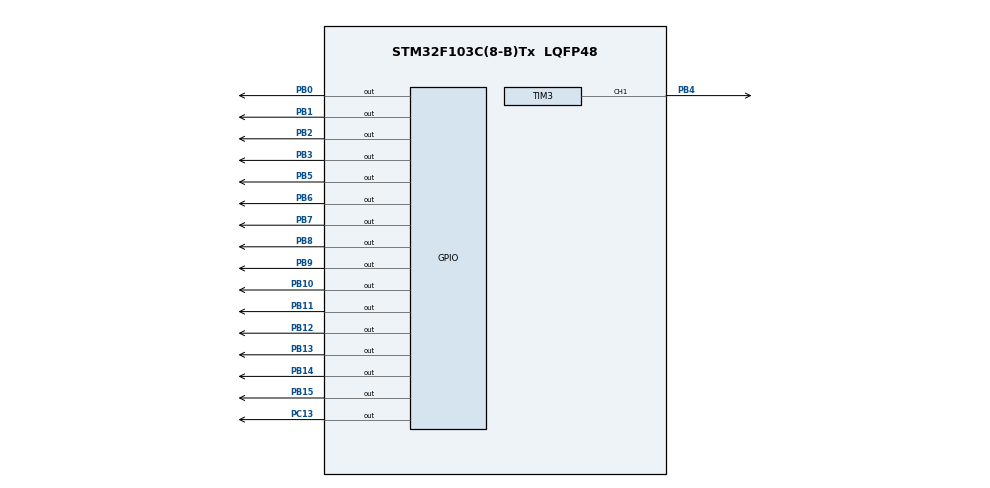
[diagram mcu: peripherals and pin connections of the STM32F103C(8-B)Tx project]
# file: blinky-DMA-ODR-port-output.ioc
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Dma.Request0=TIM1_UP
Dma.TIM1_UP.0.Direction=DMA_MEMORY_TO_PERIPH
Dma.TIM1_UP.0.Instance=DMA1_Channel5
Dma.TIM1_UP.0.MemDataAlignment=DMA_MDATAALIGN_HALFWORD
Dma.TIM1_UP.0.MemInc=DMA_MINC_ENABLE
Dma.TIM1_UP.0.Mode=DMA_CIRCULAR
Dma.TIM1_UP.0.PeriphDataAlignment=DMA_PDATAALIGN_HALFWORD
Dma.TIM1_UP.0.PeriphInc=DMA_PINC_DISABLE
Dma.TIM1_UP.0.Priority=DMA_PRIORITY_LOW
Mcu.Family=STM32F1
Mcu.Name=STM32F103C(8-B)Tx
Mcu.Package=LQFP48
NVIC.DMA1_Channel5_IRQn=true\:0\:0\:false\:false\:true\:false\:true
NVIC.PriorityGroup=NVIC_PRIORITYGROUP_4
PA13.Mode=Serial_Wire
PA13.Signal=SYS_JTMS-SWDIO
PA14.Mode=Serial_Wire
PA14.Signal=SYS_JTCK-SWCLK
PB0.Signal=GPIO_Output
PB1.Signal=GPIO_Output
PB10.Signal=GPIO_Output
PB11.Signal=GPIO_Output
PB12.Signal=GPIO_Output
PB13.Signal=GPIO_Output
PB14.Signal=GPIO_Output
PB15.Signal=GPIO_Output
PB2.Signal=GPIO_Output
PB3.Signal=GPIO_Output
PB4.Signal=S_TIM3_CH1
PB5.Signal=GPIO_Output
PB6.Signal=GPIO_Output
PB7.Signal=GPIO_Output
PB8.Signal=GPIO_Output
PB9.Signal=GPIO_Output
PC13-TAMPER-RTC.Signal=GPIO_Output
ProjectManager.HeapSize=0x200
ProjectManager.StackSize=0x400
ProjectManager.TargetToolchain=STM32CubeIDE
RCC.APB1Freq_Value=8000000
RCC.APB2Freq_Value=8000000
SH.S_TIM3_CH1.0=TIM3_CH1,PWM Generation1 CH1
TIM1.Channel-Output\ Compare1\ No\ Output=TIM_CHANNEL_1
TIM1.Period=999
TIM1.Prescaler=999
TIM1.Pulse-Output\ Compare1\ No\ Output=499
TIM3.Channel-PWM\ Generation1\ CH1=TIM_CHANNEL_1
TIM3.Period=0xff
TIM3.Prescaler=0xf
TIM3.Pulse-PWM\ Generation1\ CH1=0xea
VP_TIM1_VS_no_output1.Mode=Output Compare1 No Output
board=custom

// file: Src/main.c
/* USER CODE BEGIN Header */
/**
 ******************************************************************************
 * @file           : main.c
 * @brief          : Main program body
 ******************************************************************************
 * @attention
 *
 * <h2><center>&copy; Copyright (c) 2019 STMicroelectronics.
 * All rights reserved.</center></h2>
 *
 * This software component is licensed by ST under BSD 3-Clause license,
 * the "License"; You may not use this file except in compliance with the
 * License. You may obtain a copy of the License at:
 *                        opensource.org/licenses/BSD-3-Clause
 *
 ******************************************************************************
 */
/* USER CODE END Header */

#include "main.h"

TIM_HandleTypeDef htim1;
TIM_HandleTypeDef htim3;
DMA_HandleTypeDef hdma_tim1_up;

void SystemClock_Config(void);
static void MX_GPIO_Init(void);
static void MX_DMA_Init(void);
static void MX_TIM1_Init(void);
static void MX_TIM3_Init(void);

int main(void) {

	/* MCU Configuration--------------------------------------------------------*/

	/* Reset of all peripherals, Initializes the Flash interface and the Systick. */
	HAL_Init();

	/* Configure the system clock */
	SystemClock_Config();

	/* Initialize all configured peripherals */
	MX_GPIO_Init();
	MX_DMA_Init();
	MX_TIM1_Init();
	MX_TIM3_Init();
	/* USER CODE BEGIN 2 */
#define PATTERN_LENGTH 10
	/* In DMA step i, ODRx is set to pattern[i] bit x.
	 * Pins that are not configured as GPIO can still be used by other peripherals (alternate functions). */
	uint16_t pattern[PATTERN_LENGTH] = { 0x000f, 0x00f0, 0x0f00, 0xf000, 0x0f00, 0x00f0, 0x000f, 0x00f0, 0x0f00, 0xf000 };

	HAL_DMA_Start(&hdma_tim1_up, (uint32_t) pattern, (uint32_t) &GPIOB->ODR, PATTERN_LENGTH);
	HAL_TIM_Base_Start(&htim1);
	__HAL_TIM_ENABLE_DMA(&htim1, TIM_DMA_UPDATE);

	/* Other pins of port B can still be used (PPB4) */
	HAL_TIM_PWM_Start(&htim3, TIM_CHANNEL_1);
	/* USER CODE END 2 */

	/* Infinite loop */
	while (1) {

	}
}

void SystemClock_Config(void) {
	RCC_OscInitTypeDef RCC_OscInitStruct = { 0 };
	RCC_ClkInitTypeDef RCC_ClkInitStruct = { 0 };

	/** Initializes the CPU, AHB and APB busses clocks
	 */
	RCC_OscInitStruct.OscillatorType = RCC_OSCILLATORTYPE_HSI;
	RCC_OscInitStruct.HSIState = RCC_HSI_ON;
	RCC_OscInitStruct.HSICalibrationValue = RCC_HSICALIBRATION_DEFAULT;
	RCC_OscInitStruct.PLL.PLLState = RCC_PLL_NONE;
	if (HAL_RCC_OscConfig(&RCC_OscInitStruct) != HAL_OK) {
		Error_Handler();
	}
	/** Initializes the CPU, AHB and APB busses clocks
	 */
	RCC_ClkInitStruct.ClockType = RCC_CLOCKTYPE_HCLK | RCC_CLOCKTYPE_SYSCLK
			| RCC_CLOCKTYPE_PCLK1 | RCC_CLOCKTYPE_PCLK2;
	RCC_ClkInitStruct.SYSCLKSource = RCC_SYSCLKSOURCE_HSI;
	RCC_ClkInitStruct.AHBCLKDivider = RCC_SYSCLK_DIV1;
	RCC_ClkInitStruct.APB1CLKDivider = RCC_HCLK_DIV1;
	RCC_ClkInitStruct.APB2CLKDivider = RCC_HCLK_DIV1;

	if (HAL_RCC_ClockConfig(&RCC_ClkInitStruct, FLASH_LATENCY_0) != HAL_OK) {
		Error_Handler();
	}
}

static void MX_TIM1_Init(void) {

	TIM_MasterConfigTypeDef sMasterConfig = { 0 };
	TIM_OC_InitTypeDef sConfigOC = { 0 };
	TIM_BreakDeadTimeConfigTypeDef sBreakDeadTimeConfig = { 0 };

	htim1.Instance = TIM1;
	htim1.Init.Prescaler = 999;
	htim1.Init.CounterMode = TIM_COUNTERMODE_UP;
	htim1.Init.Period = 999;
	htim1.Init.ClockDivision = TIM_CLOCKDIVISION_DIV1;
	htim1.Init.RepetitionCounter = 0;
	htim1.Init.AutoReloadPreload = TIM_AUTORELOAD_PRELOAD_DISABLE;
	if (HAL_TIM_OC_Init(&htim1) != HAL_OK) {
		Error_Handler();
	}
	sMasterConfig.MasterOutputTrigger = TIM_TRGO_RESET;
	sMasterConfig.MasterSlaveMode = TIM_MASTERSLAVEMODE_DISABLE;
	if (HAL_TIMEx_MasterConfigSynchronization(&htim1, &sMasterConfig)
			!= HAL_OK) {
		Error_Handler();
	}
	sConfigOC.OCMode = TIM_OCMODE_TIMING;
	sConfigOC.Pulse = 499;
	sConfigOC.OCPolarity = TIM_OCPOLARITY_HIGH;
	sConfigOC.OCNPolarity = TIM_OCNPOLARITY_HIGH;
	sConfigOC.OCFastMode = TIM_OCFAST_DISABLE;
	sConfigOC.OCIdleState = TIM_OCIDLESTATE_RESET;
	sConfigOC.OCNIdleState = TIM_OCNIDLESTATE_RESET;
	if (HAL_TIM_OC_ConfigChannel(&htim1, &sConfigOC, TIM_CHANNEL_1) != HAL_OK) {
		Error_Handler();
	}
	sBreakDeadTimeConfig.OffStateRunMode = TIM_OSSR_DISABLE;
	sBreakDeadTimeConfig.OffStateIDLEMode = TIM_OSSI_DISABLE;
	sBreakDeadTimeConfig.LockLevel = TIM_LOCKLEVEL_OFF;
	sBreakDeadTimeConfig.DeadTime = 0;
	sBreakDeadTimeConfig.BreakState = TIM_BREAK_DISABLE;
	sBreakDeadTimeConfig.BreakPolarity = TIM_BREAKPOLARITY_HIGH;
	sBreakDeadTimeConfig.AutomaticOutput = TIM_AUTOMATICOUTPUT_DISABLE;
	if (HAL_TIMEx_ConfigBreakDeadTime(&htim1, &sBreakDeadTimeConfig)
			!= HAL_OK) {
		Error_Handler();
	}

}

static void MX_TIM3_Init(void) {

	TIM_MasterConfigTypeDef sMasterConfig = { 0 };
	TIM_OC_InitTypeDef sConfigOC = { 0 };

	htim3.Instance = TIM3;
	htim3.Init.Prescaler = 0xf;
	htim3.Init.CounterMode = TIM_COUNTERMODE_UP;
	htim3.Init.Period = 0xff;
	htim3.Init.ClockDivision = TIM_CLOCKDIVISION_DIV1;
	htim3.Init.AutoReloadPreload = TIM_AUTORELOAD_PRELOAD_DISABLE;
	if (HAL_TIM_PWM_Init(&htim3) != HAL_OK) {
		Error_Handler();
	}
	sMasterConfig.MasterOutputTrigger = TIM_TRGO_RESET;
	sMasterConfig.MasterSlaveMode = TIM_MASTERSLAVEMODE_DISABLE;
	if (HAL_TIMEx_MasterConfigSynchronization(&htim3, &sMasterConfig)
			!= HAL_OK) {
		Error_Handler();
	}
	sConfigOC.OCMode = TIM_OCMODE_PWM1;
	sConfigOC.Pulse = 0xea;
	sConfigOC.OCPolarity = TIM_OCPOLARITY_HIGH;
	sConfigOC.OCFastMode = TIM_OCFAST_DISABLE;
	if (HAL_TIM_PWM_ConfigChannel(&htim3, &sConfigOC, TIM_CHANNEL_1)
			!= HAL_OK) {
		Error_Handler();
	}
	HAL_TIM_MspPostInit(&htim3);

}

static void MX_DMA_Init(void) {
	/* DMA controller clock enable */
	__HAL_RCC_DMA1_CLK_ENABLE()
	;

	/* DMA interrupt init */
	/* DMA1_Channel5_IRQn interrupt configuration */
	HAL_NVIC_SetPriority(DMA1_Channel5_IRQn, 0, 0);
	HAL_NVIC_EnableIRQ(DMA1_Channel5_IRQn);

}

static void MX_GPIO_Init(void) {
	GPIO_InitTypeDef GPIO_InitStruct = { 0 };

	/* GPIO Ports Clock Enable */
	__HAL_RCC_GPIOC_CLK_ENABLE()
	;
	__HAL_RCC_GPIOB_CLK_ENABLE()
	;
	__HAL_RCC_GPIOA_CLK_ENABLE()
	;

	/*Configure GPIO pin Output Level */
	HAL_GPIO_WritePin(GPIOC, GPIO_PIN_13, GPIO_PIN_RESET);

	/*Configure GPIO pin Output Level */
	HAL_GPIO_WritePin(GPIOB,
			GPIO_PIN_0 | GPIO_PIN_1 | GPIO_PIN_2 | GPIO_PIN_10 | GPIO_PIN_11
					| GPIO_PIN_12 | GPIO_PIN_13 | GPIO_PIN_14 | GPIO_PIN_15
					| GPIO_PIN_3 | GPIO_PIN_5 | GPIO_PIN_6 | GPIO_PIN_7
					| GPIO_PIN_8 | GPIO_PIN_9, GPIO_PIN_RESET);

	/*Configure GPIO pin : PC13 */
	GPIO_InitStruct.Pin = GPIO_PIN_13;
	GPIO_InitStruct.Mode = GPIO_MODE_OUTPUT_PP;
	GPIO_InitStruct.Pull = GPIO_NOPULL;
	GPIO_InitStruct.Speed = GPIO_SPEED_FREQ_LOW;
	HAL_GPIO_Init(GPIOC, &GPIO_InitStruct);

	/*Configure GPIO pins : PB0 PB1 PB2 PB10
	 PB11 PB12 PB13 PB14
	 PB15 PB3 PB5 PB6
	 PB7 PB8 PB9 */
	GPIO_InitStruct.Pin = GPIO_PIN_0 | GPIO_PIN_1 | GPIO_PIN_2 | GPIO_PIN_10
			| GPIO_PIN_11 | GPIO_PIN_12 | GPIO_PIN_13 | GPIO_PIN_14
			| GPIO_PIN_15 | GPIO_PIN_3 | GPIO_PIN_5 | GPIO_PIN_6 | GPIO_PIN_7
			| GPIO_PIN_8 | GPIO_PIN_9;
	GPIO_InitStruct.Mode = GPIO_MODE_OUTPUT_PP;
	GPIO_InitStruct.Pull = GPIO_NOPULL;
	GPIO_InitStruct.Speed = GPIO_SPEED_FREQ_LOW;
	HAL_GPIO_Init(GPIOB, &GPIO_InitStruct);

}

void Error_Handler(void) {
}

/************************ (C) COPYRIGHT STMicroelectronics *****END OF FILE****/
